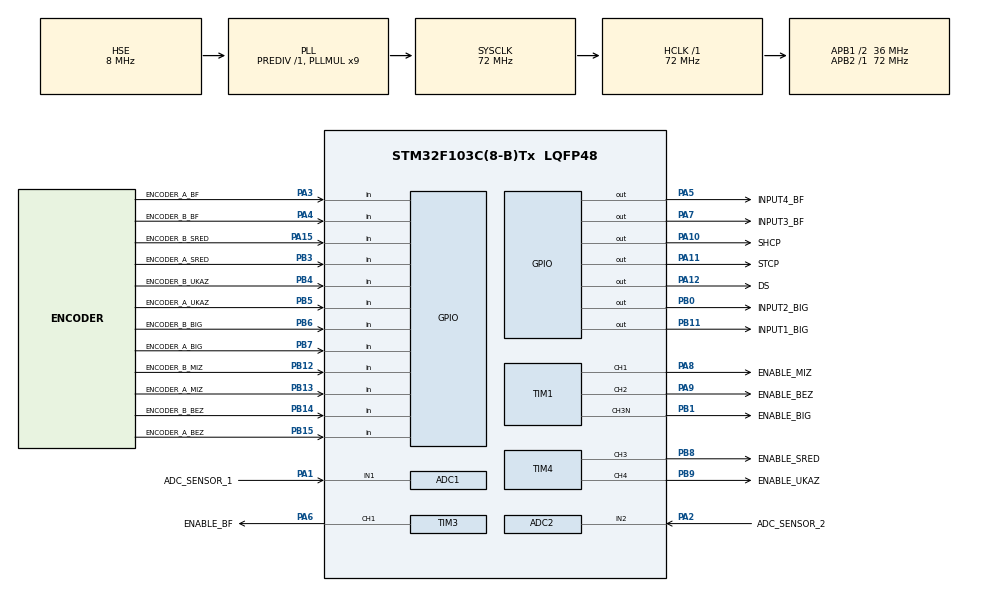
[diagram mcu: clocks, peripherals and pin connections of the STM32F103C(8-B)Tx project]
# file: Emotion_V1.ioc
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ADC1.Channel-3\#ChannelRegularConversion=ADC_CHANNEL_1
ADC1.ContinuousConvMode=ENABLE
ADC1.NbrOfConversionFlag=1
ADC1.Rank-3\#ChannelRegularConversion=1
ADC1.SamplingTime-3\#ChannelRegularConversion=ADC_SAMPLETIME_28CYCLES_5
ADC1.master=1
ADC2.Channel-0\#ChannelRegularConversion=ADC_CHANNEL_2
ADC2.ContinuousConvMode=ENABLE
ADC2.NbrOfConversionFlag=1
ADC2.Rank-0\#ChannelRegularConversion=1
ADC2.SamplingTime-0\#ChannelRegularConversion=ADC_SAMPLETIME_28CYCLES_5
Mcu.Family=STM32F1
Mcu.Name=STM32F103C(8-B)Tx
Mcu.Package=LQFP48
NVIC.PriorityGroup=NVIC_PRIORITYGROUP_4
NVIC.TIM2_IRQn=true\:0\:0\:false\:false\:true\:true\:true
PA1.GPIO_Label=ADC_SENSOR_1
PA1.Signal=ADCx_IN1
PA10.GPIO_Label=SHCP
PA10.Signal=GPIO_Output
PA11.GPIO_Label=STCP
PA11.Signal=GPIO_Output
PA12.GPIO_Label=DS
PA12.Signal=GPIO_Output
PA13.Mode=Serial_Wire
PA13.Signal=SYS_JTMS-SWDIO
PA14.Mode=Serial_Wire
PA14.Signal=SYS_JTCK-SWCLK
PA15.GPIO_Label=ENCODER_B_SRED
PA15.Signal=GPIO_Input
PA2.GPIO_Label=ADC_SENSOR_2
PA2.Signal=ADCx_IN2
PA3.GPIO_Label=ENCODER_A_BF
PA3.Signal=GPIO_Input
PA4.GPIO_Label=ENCODER_B_BF
PA4.Signal=GPIO_Input
PA5.GPIO_Label=INPUT4_BF
PA5.Signal=GPIO_Output
PA6.GPIO_Label=ENABLE_BF
PA6.Signal=S_TIM3_CH1
PA7.GPIO_Label=INPUT3_BF
PA7.Signal=GPIO_Output
PA8.GPIO_Label=ENABLE_MIZ
PA8.Signal=S_TIM1_CH1
PA9.GPIO_Label=ENABLE_BEZ
PA9.Signal=S_TIM1_CH2
PB0.GPIO_Label=INPUT2_BIG
PB0.Signal=GPIO_Output
PB1.GPIO_Label=ENABLE_BIG
PB1.Mode=PWM Generation3 CH3N
PB1.Signal=TIM1_CH3N
PB11.GPIO_Label=INPUT1_BIG
PB11.Signal=GPIO_Output
PB12.GPIO_Label=ENCODER_B_MIZ
PB12.Signal=GPIO_Input
PB13.GPIO_Label=ENCODER_A_MIZ
PB13.Signal=GPIO_Input
PB14.GPIO_Label=ENCODER_B_BEZ
PB14.Signal=GPIO_Input
PB15.GPIO_Label=ENCODER_A_BEZ
PB15.Signal=GPIO_Input
PB3.GPIO_Label=ENCODER_A_SRED
PB3.Signal=GPIO_Input
PB4.GPIO_Label=ENCODER_B_UKAZ
PB4.Signal=GPIO_Input
PB5.GPIO_Label=ENCODER_A_UKAZ
PB5.Signal=GPIO_Input
PB6.GPIO_Label=ENCODER_B_BIG
PB6.Signal=GPIO_Input
PB7.GPIO_Label=ENCODER_A_BIG
PB7.Signal=GPIO_Input
PB8.GPIO_Label=ENABLE_SRED
PB8.Signal=S_TIM4_CH3
PB9.GPIO_Label=ENABLE_UKAZ
PB9.Signal=S_TIM4_CH4
PD0-OSC_IN.Mode=HSE-External-Oscillator
PD0-OSC_IN.Signal=RCC_OSC_IN
PD1-OSC_OUT.Mode=HSE-External-Oscillator
PD1-OSC_OUT.Signal=RCC_OSC_OUT
ProjectManager.HeapSize=0x200
ProjectManager.StackSize=0x400
ProjectManager.TargetToolchain=STM32CubeIDE
RCC.ADCPresc=RCC_ADCPCLK2_DIV6
RCC.AHBFreq_Value=72000000
RCC.APB1CLKDivider=RCC_HCLK_DIV2
RCC.APB1Freq_Value=36000000
RCC.APB1TimFreq_Value=72000000
RCC.APB2Freq_Value=72000000
RCC.APB2TimFreq_Value=72000000
RCC.HCLKFreq_Value=72000000
RCC.PLLMUL=RCC_PLL_MUL9
RCC.PLLSourceVirtual=RCC_PLLSOURCE_HSE
RCC.SYSCLKFreq_VALUE=72000000
RCC.SYSCLKSource=RCC_SYSCLKSOURCE_PLLCLK
RCC.USBFreq_Value=72000000
SH.ADCx_IN1.0=ADC1_IN1,IN1
SH.ADCx_IN2.0=ADC2_IN2,IN2
SH.S_TIM1_CH1.0=TIM1_CH1,PWM Generation1 CH1
SH.S_TIM1_CH2.0=TIM1_CH2,PWM Generation2 CH2
SH.S_TIM3_CH1.0=TIM3_CH1,PWM Generation1 CH1
SH.S_TIM4_CH3.0=TIM4_CH3,PWM Generation3 CH3
SH.S_TIM4_CH4.0=TIM4_CH4,PWM Generation4 CH4
TIM1.Channel-PWM\ Generation1\ CH1=TIM_CHANNEL_1
TIM1.Channel-PWM\ Generation2\ CH2=TIM_CHANNEL_2
TIM1.Channel-PWM\ Generation3\ CH3N=TIM_CHANNEL_3
TIM2.Period=999
TIM2.Prescaler=719
TIM3.Channel-PWM\ Generation1\ CH1=TIM_CHANNEL_1
TIM4.Channel-PWM\ Generation3\ CH3=TIM_CHANNEL_3
TIM4.Channel-PWM\ Generation4\ CH4=TIM_CHANNEL_4
VP_TIM1_VS_ClockSourceINT.Mode=Internal
VP_TIM2_VS_ClockSourceINT.Mode=Internal
VP_TIM3_VS_ClockSourceINT.Mode=Internal
VP_TIM4_VS_ClockSourceINT.Mode=Internal
board=custom

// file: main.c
/* USER CODE BEGIN Header */
/**
  ******************************************************************************
  * @file           : main.c
  * @brief          : Main program body
  ******************************************************************************
  * @attention
  *
  * <h2><center>&copy; Copyright (c) 2022 STMicroelectronics.
  * All rights reserved.</center></h2>
  *
  * This software component is licensed by ST under BSD 3-Clause license,
  * the "License"; You may not use this file except in compliance with the
  * License. You may obtain a copy of the License at:
  *                        opensource.org/licenses/BSD-3-Clause
  *
  ******************************************************************************
  */
/* USER CODE END Header */
#include "main.h"

/* USER CODE BEGIN PD */
#define VCC 3.3
/* USER CODE END PD */

ADC_HandleTypeDef hadc1;
ADC_HandleTypeDef hadc2;

TIM_HandleTypeDef htim1;
TIM_HandleTypeDef htim2;
TIM_HandleTypeDef htim3;
TIM_HandleTypeDef htim4;

void SystemClock_Config(void);
static void MX_GPIO_Init(void);
static void MX_ADC1_Init(void);
static void MX_TIM1_Init(void);
static void MX_TIM3_Init(void);
static void MX_TIM4_Init(void);
static void MX_TIM2_Init(void);
static void MX_ADC2_Init(void);

int main(void)
{

  /* MCU Configuration--------------------------------------------------------*/

  /* Reset of all peripherals, Initializes the Flash interface and the Systick. */
  HAL_Init();

  /* Configure the system clock */
  SystemClock_Config();

  /* Initialize all configured peripherals */
  MX_GPIO_Init();
  MX_ADC1_Init();
  MX_TIM1_Init();
  MX_TIM3_Init();
  MX_TIM4_Init();
  MX_TIM2_Init();
  MX_ADC2_Init();
  /* USER CODE BEGIN 2 */

  HAL_TIM_Base_Start_IT(&htim2);
  // запуск таймера для прерываний каждые 10 мс для Sensors

  HAL_ADCEx_Calibration_Start(&hadc1);
  HAL_ADCEx_Calibration_Start(&hadc2);
  // Калибровка АЦП (не знаю зачем)

  HAL_ADC_Start(&hadc1);
  HAL_ADC_Start(&hadc2);
  // запуск преобразования двух АЦП

  /* USER CODE END 2 */

  /* Infinite loop */
  while (1)
  {

  }
}

void SystemClock_Config(void)
{
  RCC_OscInitTypeDef RCC_OscInitStruct = {0};
  RCC_ClkInitTypeDef RCC_ClkInitStruct = {0};
  RCC_PeriphCLKInitTypeDef PeriphClkInit = {0};

  /** Initializes the RCC Oscillators according to the specified parameters
  * in the RCC_OscInitTypeDef structure.
  */
  RCC_OscInitStruct.OscillatorType = RCC_OSCILLATORTYPE_HSE;
  RCC_OscInitStruct.HSEState = RCC_HSE_ON;
  RCC_OscInitStruct.HSEPredivValue = RCC_HSE_PREDIV_DIV1;
  RCC_OscInitStruct.HSIState = RCC_HSI_ON;
  RCC_OscInitStruct.PLL.PLLState = RCC_PLL_ON;
  RCC_OscInitStruct.PLL.PLLSource = RCC_PLLSOURCE_HSE;
  RCC_OscInitStruct.PLL.PLLMUL = RCC_PLL_MUL9;
  if (HAL_RCC_OscConfig(&RCC_OscInitStruct) != HAL_OK)
  {
    Error_Handler();
  }
  /** Initializes the CPU, AHB and APB buses clocks
  */
  RCC_ClkInitStruct.ClockType = RCC_CLOCKTYPE_HCLK|RCC_CLOCKTYPE_SYSCLK
                              |RCC_CLOCKTYPE_PCLK1|RCC_CLOCKTYPE_PCLK2;
  RCC_ClkInitStruct.SYSCLKSource = RCC_SYSCLKSOURCE_PLLCLK;
  RCC_ClkInitStruct.AHBCLKDivider = RCC_SYSCLK_DIV1;
  RCC_ClkInitStruct.APB1CLKDivider = RCC_HCLK_DIV2;
  RCC_ClkInitStruct.APB2CLKDivider = RCC_HCLK_DIV1;

  if (HAL_RCC_ClockConfig(&RCC_ClkInitStruct, FLASH_LATENCY_2) != HAL_OK)
  {
    Error_Handler();
  }
  PeriphClkInit.PeriphClockSelection = RCC_PERIPHCLK_ADC;
  PeriphClkInit.AdcClockSelection = RCC_ADCPCLK2_DIV6;
  if (HAL_RCCEx_PeriphCLKConfig(&PeriphClkInit) != HAL_OK)
  {
    Error_Handler();
  }
}

static void MX_ADC1_Init(void)
{

  ADC_ChannelConfTypeDef sConfig = {0};

  /** Common config
  */
  hadc1.Instance = ADC1;
  hadc1.Init.ScanConvMode = ADC_SCAN_DISABLE;
  hadc1.Init.ContinuousConvMode = ENABLE;
  hadc1.Init.DiscontinuousConvMode = DISABLE;
  hadc1.Init.ExternalTrigConv = ADC_SOFTWARE_START;
  hadc1.Init.DataAlign = ADC_DATAALIGN_RIGHT;
  hadc1.Init.NbrOfConversion = 1;
  if (HAL_ADC_Init(&hadc1) != HAL_OK)
  {
    Error_Handler();
  }
  /** Configure Regular Channel
  */
  sConfig.Channel = ADC_CHANNEL_1;
  sConfig.Rank = ADC_REGULAR_RANK_1;
  sConfig.SamplingTime = ADC_SAMPLETIME_28CYCLES_5;
  if (HAL_ADC_ConfigChannel(&hadc1, &sConfig) != HAL_OK)
  {
    Error_Handler();
  }

}

static void MX_ADC2_Init(void)
{

  ADC_ChannelConfTypeDef sConfig = {0};

  /** Common config
  */
  hadc2.Instance = ADC2;
  hadc2.Init.ScanConvMode = ADC_SCAN_DISABLE;
  hadc2.Init.ContinuousConvMode = ENABLE;
  hadc2.Init.DiscontinuousConvMode = DISABLE;
  hadc2.Init.ExternalTrigConv = ADC_SOFTWARE_START;
  hadc2.Init.DataAlign = ADC_DATAALIGN_RIGHT;
  hadc2.Init.NbrOfConversion = 1;
  if (HAL_ADC_Init(&hadc2) != HAL_OK)
  {
    Error_Handler();
  }
  /** Configure Regular Channel
  */
  sConfig.Channel = ADC_CHANNEL_2;
  sConfig.Rank = ADC_REGULAR_RANK_1;
  sConfig.SamplingTime = ADC_SAMPLETIME_28CYCLES_5;
  if (HAL_ADC_ConfigChannel(&hadc2, &sConfig) != HAL_OK)
  {
    Error_Handler();
  }

}

static void MX_TIM1_Init(void)
{

  TIM_ClockConfigTypeDef sClockSourceConfig = {0};
  TIM_MasterConfigTypeDef sMasterConfig = {0};
  TIM_OC_InitTypeDef sConfigOC = {0};
  TIM_BreakDeadTimeConfigTypeDef sBreakDeadTimeConfig = {0};

  htim1.Instance = TIM1;
  htim1.Init.Prescaler = 0;
  htim1.Init.CounterMode = TIM_COUNTERMODE_UP;
  htim1.Init.Period = 65535;
  htim1.Init.ClockDivision = TIM_CLOCKDIVISION_DIV1;
  htim1.Init.RepetitionCounter = 0;
  htim1.Init.AutoReloadPreload = TIM_AUTORELOAD_PRELOAD_DISABLE;
  if (HAL_TIM_Base_Init(&htim1) != HAL_OK)
  {
    Error_Handler();
  }
  sClockSourceConfig.ClockSource = TIM_CLOCKSOURCE_INTERNAL;
  if (HAL_TIM_ConfigClockSource(&htim1, &sClockSourceConfig) != HAL_OK)
  {
    Error_Handler();
  }
  if (HAL_TIM_PWM_Init(&htim1) != HAL_OK)
  {
    Error_Handler();
  }
  sMasterConfig.MasterOutputTrigger = TIM_TRGO_RESET;
  sMasterConfig.MasterSlaveMode = TIM_MASTERSLAVEMODE_DISABLE;
  if (HAL_TIMEx_MasterConfigSynchronization(&htim1, &sMasterConfig) != HAL_OK)
  {
    Error_Handler();
  }
  sConfigOC.OCMode = TIM_OCMODE_PWM1;
  sConfigOC.Pulse = 0;
  sConfigOC.OCPolarity = TIM_OCPOLARITY_HIGH;
  sConfigOC.OCNPolarity = TIM_OCNPOLARITY_HIGH;
  sConfigOC.OCFastMode = TIM_OCFAST_DISABLE;
  sConfigOC.OCIdleState = TIM_OCIDLESTATE_RESET;
  sConfigOC.OCNIdleState = TIM_OCNIDLESTATE_RESET;
  if (HAL_TIM_PWM_ConfigChannel(&htim1, &sConfigOC, TIM_CHANNEL_1) != HAL_OK)
  {
    Error_Handler();
  }
  if (HAL_TIM_PWM_ConfigChannel(&htim1, &sConfigOC, TIM_CHANNEL_2) != HAL_OK)
  {
    Error_Handler();
  }
  if (HAL_TIM_PWM_ConfigChannel(&htim1, &sConfigOC, TIM_CHANNEL_3) != HAL_OK)
  {
    Error_Handler();
  }
  sBreakDeadTimeConfig.OffStateRunMode = TIM_OSSR_DISABLE;
  sBreakDeadTimeConfig.OffStateIDLEMode = TIM_OSSI_DISABLE;
  sBreakDeadTimeConfig.LockLevel = TIM_LOCKLEVEL_OFF;
  sBreakDeadTimeConfig.DeadTime = 0;
  sBreakDeadTimeConfig.BreakState = TIM_BREAK_DISABLE;
  sBreakDeadTimeConfig.BreakPolarity = TIM_BREAKPOLARITY_HIGH;
  sBreakDeadTimeConfig.AutomaticOutput = TIM_AUTOMATICOUTPUT_DISABLE;
  if (HAL_TIMEx_ConfigBreakDeadTime(&htim1, &sBreakDeadTimeConfig) != HAL_OK)
  {
    Error_Handler();
  }
  HAL_TIM_MspPostInit(&htim1);

}

static void MX_TIM2_Init(void)
{

  TIM_ClockConfigTypeDef sClockSourceConfig = {0};
  TIM_MasterConfigTypeDef sMasterConfig = {0};

  htim2.Instance = TIM2;
  htim2.Init.Prescaler = 719;
  htim2.Init.CounterMode = TIM_COUNTERMODE_UP;
  htim2.Init.Period = 999;
  htim2.Init.ClockDivision = TIM_CLOCKDIVISION_DIV1;
  htim2.Init.AutoReloadPreload = TIM_AUTORELOAD_PRELOAD_DISABLE;
  if (HAL_TIM_Base_Init(&htim2) != HAL_OK)
  {
    Error_Handler();
  }
  sClockSourceConfig.ClockSource = TIM_CLOCKSOURCE_INTERNAL;
  if (HAL_TIM_ConfigClockSource(&htim2, &sClockSourceConfig) != HAL_OK)
  {
    Error_Handler();
  }
  sMasterConfig.MasterOutputTrigger = TIM_TRGO_RESET;
  sMasterConfig.MasterSlaveMode = TIM_MASTERSLAVEMODE_DISABLE;
  if (HAL_TIMEx_MasterConfigSynchronization(&htim2, &sMasterConfig) != HAL_OK)
  {
    Error_Handler();
  }

}

static void MX_TIM3_Init(void)
{

  TIM_ClockConfigTypeDef sClockSourceConfig = {0};
  TIM_MasterConfigTypeDef sMasterConfig = {0};
  TIM_OC_InitTypeDef sConfigOC = {0};

  htim3.Instance = TIM3;
  htim3.Init.Prescaler = 0;
  htim3.Init.CounterMode = TIM_COUNTERMODE_UP;
  htim3.Init.Period = 65535;
  htim3.Init.ClockDivision = TIM_CLOCKDIVISION_DIV1;
  htim3.Init.AutoReloadPreload = TIM_AUTORELOAD_PRELOAD_DISABLE;
  if (HAL_TIM_Base_Init(&htim3) != HAL_OK)
  {
    Error_Handler();
  }
  sClockSourceConfig.ClockSource = TIM_CLOCKSOURCE_INTERNAL;
  if (HAL_TIM_ConfigClockSource(&htim3, &sClockSourceConfig) != HAL_OK)
  {
    Error_Handler();
  }
  if (HAL_TIM_PWM_Init(&htim3) != HAL_OK)
  {
    Error_Handler();
  }
  sMasterConfig.MasterOutputTrigger = TIM_TRGO_RESET;
  sMasterConfig.MasterSlaveMode = TIM_MASTERSLAVEMODE_DISABLE;
  if (HAL_TIMEx_MasterConfigSynchronization(&htim3, &sMasterConfig) != HAL_OK)
  {
    Error_Handler();
  }
  sConfigOC.OCMode = TIM_OCMODE_PWM1;
  sConfigOC.Pulse = 0;
  sConfigOC.OCPolarity = TIM_OCPOLARITY_HIGH;
  sConfigOC.OCFastMode = TIM_OCFAST_DISABLE;
  if (HAL_TIM_PWM_ConfigChannel(&htim3, &sConfigOC, TIM_CHANNEL_1) != HAL_OK)
  {
    Error_Handler();
  }
  HAL_TIM_MspPostInit(&htim3);

}

static void MX_TIM4_Init(void)
{

  TIM_ClockConfigTypeDef sClockSourceConfig = {0};
  TIM_MasterConfigTypeDef sMasterConfig = {0};
  TIM_OC_InitTypeDef sConfigOC = {0};

  htim4.Instance = TIM4;
  htim4.Init.Prescaler = 0;
  htim4.Init.CounterMode = TIM_COUNTERMODE_UP;
  htim4.Init.Period = 65535;
  htim4.Init.ClockDivision = TIM_CLOCKDIVISION_DIV1;
  htim4.Init.AutoReloadPreload = TIM_AUTORELOAD_PRELOAD_DISABLE;
  if (HAL_TIM_Base_Init(&htim4) != HAL_OK)
  {
    Error_Handler();
  }
  sClockSourceConfig.ClockSource = TIM_CLOCKSOURCE_INTERNAL;
  if (HAL_TIM_ConfigClockSource(&htim4, &sClockSourceConfig) != HAL_OK)
  {
    Error_Handler();
  }
  if (HAL_TIM_PWM_Init(&htim4) != HAL_OK)
  {
    Error_Handler();
  }
  sMasterConfig.MasterOutputTrigger = TIM_TRGO_RESET;
  sMasterConfig.MasterSlaveMode = TIM_MASTERSLAVEMODE_DISABLE;
  if (HAL_TIMEx_MasterConfigSynchronization(&htim4, &sMasterConfig) != HAL_OK)
  {
    Error_Handler();
  }
  sConfigOC.OCMode = TIM_OCMODE_PWM1;
  sConfigOC.Pulse = 0;
  sConfigOC.OCPolarity = TIM_OCPOLARITY_HIGH;
  sConfigOC.OCFastMode = TIM_OCFAST_DISABLE;
  if (HAL_TIM_PWM_ConfigChannel(&htim4, &sConfigOC, TIM_CHANNEL_3) != HAL_OK)
  {
    Error_Handler();
  }
  if (HAL_TIM_PWM_ConfigChannel(&htim4, &sConfigOC, TIM_CHANNEL_4) != HAL_OK)
  {
    Error_Handler();
  }
  HAL_TIM_MspPostInit(&htim4);

}

static void MX_GPIO_Init(void)
{
  GPIO_InitTypeDef GPIO_InitStruct = {0};

  /* GPIO Ports Clock Enable */
  __HAL_RCC_GPIOD_CLK_ENABLE();
  __HAL_RCC_GPIOA_CLK_ENABLE();
  __HAL_RCC_GPIOB_CLK_ENABLE();

  /*Configure GPIO pin Output Level */
  HAL_GPIO_WritePin(GPIOA, INPUT4_BF_Pin|INPUT3_BF_Pin|SHCP_Pin|STCP_Pin
                          |DS_Pin, GPIO_PIN_RESET);

  /*Configure GPIO pin Output Level */
  HAL_GPIO_WritePin(GPIOB, INPUT2_BIG_Pin|INPUT1_BIG_Pin, GPIO_PIN_RESET);

  /*Configure GPIO pins : ENCODER_A_BF_Pin ENCODER_B_BF_Pin ENCODER_B_SRED_Pin */
  GPIO_InitStruct.Pin = ENCODER_A_BF_Pin|ENCODER_B_BF_Pin|ENCODER_B_SRED_Pin;
  GPIO_InitStruct.Mode = GPIO_MODE_INPUT;
  GPIO_InitStruct.Pull = GPIO_NOPULL;
  HAL_GPIO_Init(GPIOA, &GPIO_InitStruct);

  /*Configure GPIO pins : INPUT4_BF_Pin INPUT3_BF_Pin SHCP_Pin STCP_Pin
                           DS_Pin */
  GPIO_InitStruct.Pin = INPUT4_BF_Pin|INPUT3_BF_Pin|SHCP_Pin|STCP_Pin
                          |DS_Pin;
  GPIO_InitStruct.Mode = GPIO_MODE_OUTPUT_PP;
  GPIO_InitStruct.Pull = GPIO_NOPULL;
  GPIO_InitStruct.Speed = GPIO_SPEED_FREQ_LOW;
  HAL_GPIO_Init(GPIOA, &GPIO_InitStruct);

  /*Configure GPIO pins : INPUT2_BIG_Pin INPUT1_BIG_Pin */
  GPIO_InitStruct.Pin = INPUT2_BIG_Pin|INPUT1_BIG_Pin;
  GPIO_InitStruct.Mode = GPIO_MODE_OUTPUT_PP;
  GPIO_InitStruct.Pull = GPIO_NOPULL;
  GPIO_InitStruct.Speed = GPIO_SPEED_FREQ_LOW;
  HAL_GPIO_Init(GPIOB, &GPIO_InitStruct);

  /*Configure GPIO pins : ENCODER_B_MIZ_Pin ENCODER_A_MIZ_Pin ENCODER_B_BEZ_Pin ENCODER_A_BEZ_Pin
                           ENCODER_A_SRED_Pin ENCODER_B_UKAZ_Pin ENCODER_A_UKAZ_Pin ENCODER_B_BIG_Pin
                           ENCODER_A_BIG_Pin */
  GPIO_InitStruct.Pin = ENCODER_B_MIZ_Pin|ENCODER_A_MIZ_Pin|ENCODER_B_BEZ_Pin|ENCODER_A_BEZ_Pin
                          |ENCODER_A_SRED_Pin|ENCODER_B_UKAZ_Pin|ENCODER_A_UKAZ_Pin|ENCODER_B_BIG_Pin
                          |ENCODER_A_BIG_Pin;
  GPIO_InitStruct.Mode = GPIO_MODE_INPUT;
  GPIO_InitStruct.Pull = GPIO_NOPULL;
  HAL_GPIO_Init(GPIOB, &GPIO_InitStruct);

}

void Error_Handler(void)
{
  __disable_irq();
  while (1)
  {
  }
}

/************************ (C) COPYRIGHT STMicroelectronics *****END OF FILE****/
